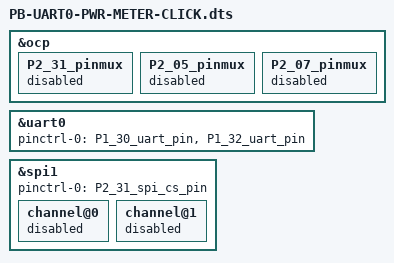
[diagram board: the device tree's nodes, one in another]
/*
 * Copyright (C) 2019 Duncan Cameron <duncan.cameron@ecs.vuw.ac.nz>
 *
 * This program is free software; you can redistribute it and/or modify
 * it under the terms of the GNU General Public License version 2 as
 * published by the Free Software Foundation.
 *
 * https://www.mikroe.com/pwr-meter-click
 * https://download.mikroe.com/documents/add-on-boards/click/pwr-meter/pwr-meter-click-schematic-v100.pdf
 */

/dts-v1/;
/plugin/;

#include <dt-bindings/gpio/gpio.h>
#include <dt-bindings/pinctrl/am33xx.h>
#include <dt-bindings/interrupt-controller/irq.h>

/ {
	/*
	 * Free up the pins used by the cape from the pinmux helpers.
	 */
	fragment@0 {
		target = <&ocp>;
		__overlay__ {
			P2_31_pinmux { status = "disabled"; };	/* gpio0_19 - CS */
			P2_05_pinmux { status = "disabled"; };	/* gpio0_42 - TXD */
			P2_07_pinmux { status = "disabled"; };	/* gpio0_43 - RXD */
		};
	};

	fragment@1 {
		target = <&uart0>;
		__overlay__ {
			status = "okay";
			pinctrl-names = "default";
			pinctrl-0 = <
				&P1_30_uart_pin
				&P1_32_uart_pin
			>;
		};
	};

	fragment@2 {
		target = <&spi1>;
		__overlay__ {
			status = "okay";
			pinctrl-names = "default";
			pinctrl-0 = <
				&P2_31_spi_cs_pin
			>;

			channel@0{ status = "disabled"; };
			channel@1{ status = "disabled"; };
		};
};
};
